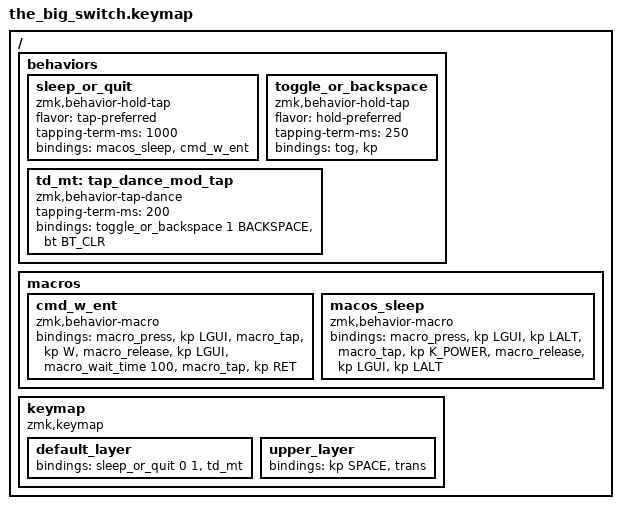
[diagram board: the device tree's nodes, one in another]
/*
 * Copyright (c) 2022 The ZMK Contributors
 *
 * SPDX-License-Identifier: MIT
 */

#include <behaviors.dtsi>
#include <dt-bindings/zmk/keys.h>
#include <dt-bindings/zmk/bt.h>

/ {
    behaviors {
        sleep_or_quit: sleep_or_quit {
            compatible = "zmk,behavior-hold-tap";
            #binding-cells = <2>;
            flavor = "tap-preferred";
            tapping-term-ms = <1000>;
            bindings = <&macos_sleep>, <&cmd_w_ent>;
        };
        toggle_or_backspace: toggle_or_backspace{
            compatible = "zmk,behavior-hold-tap";
            #binding-cells = <2>;
            flavor = "hold-preferred";
            tapping-term-ms = <250>;
            bindings = <&tog>, <&kp>;
        };
        td_mt: tap_dance_mod_tap {
            compatible = "zmk,behavior-tap-dance";
            #binding-cells = <0>;
            tapping-term-ms = <200>;
            bindings = <&toggle_or_backspace 1 BACKSPACE>, <&bt BT_CLR>;
        };
    };
    macros {
        cmd_w_ent: cmd_w_ent {
            compatible = "zmk,behavior-macro";
            #binding-cells = <0>;
            bindings
                = <&macro_press &kp LGUI>
                , <&macro_tap &kp W>
                , <&macro_release &kp LGUI>
                , <&macro_wait_time 100>
                , <&macro_tap &kp RET>
                ;
        };
        macos_sleep: macos_sleep {
            compatible = "zmk,behavior-macro";
            #binding-cells = <0>;
            bindings
                = <&macro_press &kp LGUI &kp LALT>
                , <&macro_tap &kp K_POWER>
                , <&macro_release &kp LGUI &kp LALT>
                ;
        };
    };
    keymap {
        compatible = "zmk,keymap";

        default_layer {
            bindings = <
               // press -> quit zoom call, hold -> macOS Sleep
               &sleep_or_quit 0 1
               // press -> back one slide, hold -> toggle layer
               &td_mt
            >;
        };
        upper_layer {
            bindings = <
               // advance slide
               &kp SPACE
               &trans
            >;
        };
    };
};
